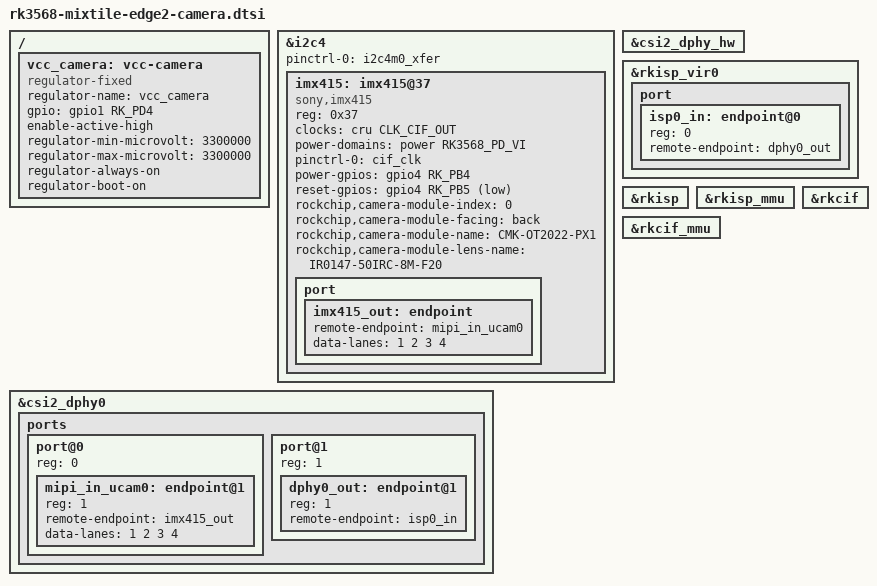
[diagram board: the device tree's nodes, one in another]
/ {
	vcc_camera: vcc-camera {
                compatible = "regulator-fixed";
                regulator-name = "vcc_camera";
                gpio = <&gpio1 RK_PD4 GPIO_ACTIVE_HIGH>;
                enable-active-high;
                regulator-min-microvolt = <3300000>;
                regulator-max-microvolt = <3300000>;
                regulator-always-on;
                regulator-boot-on;
        };
};

&i2c4 {
        status = "okay";
        pinctrl-names = "default";
        pinctrl-0 = <&i2c4m0_xfer>;


        imx415: imx415@37 {
                status = "okay";
                compatible = "sony,imx415";
                reg = <0x37>;
		clocks = <&cru CLK_CIF_OUT>;
                clock-names = "xvclk";
                power-domains = <&power RK3568_PD_VI>;
                pinctrl-names = "default";
                pinctrl-0 = <&cif_clk>;
                power-gpios = <&gpio4 RK_PB4 GPIO_ACTIVE_HIGH>;
		reset-gpios = <&gpio4 RK_PB5 GPIO_ACTIVE_LOW>;

                rockchip,camera-module-index = <0>;
                rockchip,camera-module-facing = "back";
                rockchip,camera-module-name = "CMK-OT2022-PX1";
                rockchip,camera-module-lens-name = "IR0147-50IRC-8M-F20";

                port {
                        imx415_out: endpoint {
                                remote-endpoint = <&mipi_in_ucam0>;
                                data-lanes = <1 2 3 4>;
                        };
                };
        };
};

&csi2_dphy_hw {
        status = "okay";
};

&csi2_dphy0 {
        status = "okay";

        ports {
                #address-cells = <1>;
                #size-cells = <0>;

                port@0 {
                        reg = <0>;
                        #address-cells = <1>;
                        #size-cells = <0>;

                        mipi_in_ucam0: endpoint@1 {
                                reg = <1>;
                                remote-endpoint = <&imx415_out>;
                                data-lanes = <1 2 3 4>;
                        };

		};
                port@1 {
                        reg = <1>;
                        #address-cells = <1>;
                        #size-cells = <0>;

                        dphy0_out: endpoint@1 {
                                reg = <1>;
                                remote-endpoint = <&isp0_in>;
                        };
                };
        };
};

&rkisp_vir0 {
        status = "okay";

        port {
                #address-cells = <1>;
                #size-cells = <0>;

                isp0_in: endpoint@0 {
                        reg = <0>;
                        remote-endpoint = <&dphy0_out>;
                };
        };
};

&rkisp {
        status = "okay";
};

&rkisp_mmu {
        status = "okay";
};

&rkcif_mmu {
        status = "okay";
};

&rkcif {
        status = "okay";
};
